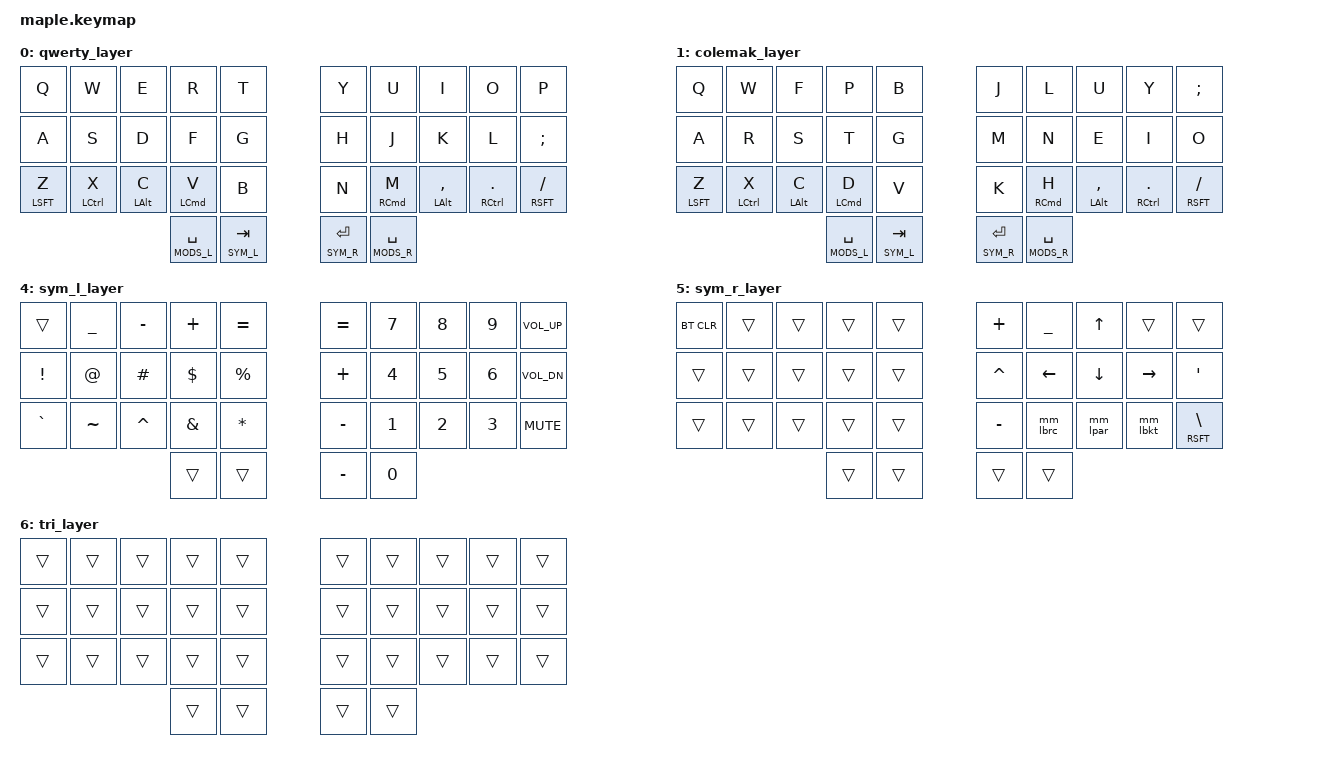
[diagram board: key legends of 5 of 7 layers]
/*
 * Copyright (c) 2020 The ZMK Contributors
 *
 * SPDX-License-Identifier: MIT
 */

#include <behaviors.dtsi>
#include <dt-bindings/zmk/keys.h>
#include <dt-bindings/zmk/bt.h>

#define QWERTY   0
#define COLEMAK  1 // DHm
#define MODS_L   2
#define MODS_R   3
#define SYM_L    4
#define SYM_R    5

&mt {
  // flavor = "tap-preferred"; // disabled here to override only for &hm keys // https://zmk.dev/docs/behaviors/hold-tap#flavors
  // tapping_term_ms = <200>;
};

/ {

  behaviors {
    // positional hold-taps (home-row)
    // - don't work with combo-arrow-keys
    lht: left_hold_tap {
      compatible = "zmk,behavior-hold-tap";
      label = "LEFT_HOLD_TAP";
      #binding-cells = <2>;
      flavor = "tap-preferred";
      tapping-term-ms = <175>;
      quick-tap-ms = <75>;
      bindings = <&kp>, <&kp>;
      hold-trigger-key-positions = <5 6 7 8 9 15 16 17 18 19 25 26 27 28 29>; // all right-side key-positions
      // <5 6 7 8 9 15 16 17 18 19 25 26 27 28 29 32 33>; // all right-side key-positions
    };
    rht: right_hold_tap {
      compatible = "zmk,behavior-hold-tap";
      label = "RIGHT_HOLD_TAP";
      #binding-cells = <2>;
      flavor = "tap-preferred";
      tapping-term-ms = <175>;
      quick-tap-ms = <75>;
      bindings = <&kp>, <&kp>;
      hold-trigger-key-positions = <0 1 2 3 4 10 11 12 13 14 20 21 22 23 24>; // all left-side key-positions
      // <0 1 2 3 4 10 11 12 13 14 20 21 22 23 24 30 31>; // all left-side key-positions
    };
    // custom behavior for only homerow-mod keys (todo: test these instead of lht&rht)
    // - should work with combo arrow-keys
    hm: homerow_mods {
      compatible = "zmk,behavior-hold-tap";
      label = "HOMEROW_MODS";
      #binding-cells = <2>;
      tapping-term-ms = <150>;
      quick-tap-ms = <0>;
      flavor = "tap-preferred";
      bindings = <&kp>, <&kp>;
    };
    // mod-morphs
    mm_lbrc: mod_morph_shft_rbrc {
      compatible = "zmk,behavior-mod-morph";
      label = "MM_SHFT_LBRC_TO_RBRC";
      #binding-cells = <0>;
      bindings = <&kp LBRC>, <&kp RBRC>;
      mods = <(MOD_LSFT|MOD_RSFT)>;
    };
    mm_lpar: mod_morph_shft_rpar {
      compatible = "zmk,behavior-mod-morph";
      label = "MM_SHFT_LPAR_TO_RPAR";
      #binding-cells = <0>;
      bindings = <&kp LPAR>, <&kp RPAR>;
      mods = <(MOD_LSFT|MOD_RSFT)>;
    };
    mm_lbkt: mod_morph_shft_rbkt {
      compatible = "zmk,behavior-mod-morph";
      label = "MM_SHFT_LBKT_TO_RBKT";
      #binding-cells = <0>;
      bindings = <&kp LBKT>, <&kp RBKT>;
      mods = <(MOD_LSFT|MOD_RSFT)>;
    };
    mm_bspc: mod_morph_shft_del {
      compatible = "zmk,behavior-mod-morph";
      label = "MM_SHFT_BSPC_TO_DEL";
      #binding-cells = <0>;
      bindings = <&kp BSPC>, <&kp DEL>;
      mods = <(MOD_LSFT|MOD_RSFT)>;
      keep-mods = <(MOD_LSFT)>;
    };
    // custom: haven't got tap-dance repeat arrow keys to work yet
    // - needed for home-row mods and arrow-combos on same base layer
    // - could maybe be combined with quick-tap to fix repeat problem
    // td_combo_right: tap_dance_combo_right {
    //   compatible = "zmk,behavior-tap-dance";
    //   label = "TD_COMBO_RIGHT";
    //   #binding-cells = <0>;
    //   tapping-term-ms = <200>;
    //   bindings =<&mt (RCTRL|RSFT) RIGHT>, <&kp RIGHT>;
    // };
    // td_combo_down: tap_dance_combo_down {
    //   compatible = "zmk,behavior-tap-dance";
    //   label = "TD_COMBO_DOWN";
    //   #binding-cells = <0>;
    //   tapping-term-ms = <200>;
    //   bindings =<&mt (LALT|RCTRL) DOWN>, <&kp DOWN>;
    // };
    // td_combo_left: tap_dance_combo_left {
    //   compatible = "zmk,behavior-tap-dance";
    //   label = "TD_COMBO_LEFT";
    //   #binding-cells = <0>;
    //   tapping-term-ms = <200>;
    //   bindings =<&mt (RCMD|LALT) LEFT>, <&kp LEFT>;
    // };
  };

  // macros {
  //   mc_hm_cmd: mc_hm_cmd {
  //     label = "MACRO_HOMEROW_CMD";
  //     compatible = "zmk,behavior-macro";
  //     #binding-cells = <0>;
  //     bindings = <&macro_press &kp LSHFT>, <&macro_tap &kp Z &kp M &kp K>, <&macro_release &kp LSHFT>;
  //   };
  // };


  //          key-positions
  //  0  1  2  3  4    5  6  7  8  9
  // 10 11 12 13 14   15 16 17 18 19
  // 20 21 22 23 24   25 26 27 28 29
  //          30 31   32 33

  combos {
    compatible = "zmk,combos";
    combo_tab {
      timeout-ms = <50>;
      key-positions = <0 1>;
      bindings = <&kp TAB>;
    };
    combo_esc {
      timeout-ms = <50>;
      key-positions = <10 11>;
      bindings = <&mt (LSFT|LCTRL) ESC>;
    };
    combo_up {
      timeout-ms = <50>;
      key-positions = <7 8>;
      bindings = <&kp UP>;
    };
    combo_right {
      timeout-ms = <50>;
      key-positions = <18 19>;
      // bindings = <&mt (RCTRL|RSFT) RIGHT>;
      bindings = <&kp RIGHT>;
    };
    combo_down {
      timeout-ms = <50>;
      key-positions = <17 18>;
      // bindings = <&mt (LALT|RCTRL) DOWN>;
      bindings = <&kp DOWN>;
    };
    combo_left {
      timeout-ms = <50>;
      key-positions = <16 17>;
      // bindings = <&mt (RCMD|LALT) LEFT>;
      bindings = <&kp LEFT>;
    };
    combo_bspc {
      timeout-ms = <50>;
      key-positions = <8 9>;
      bindings = <&mm_bspc>;
    };
    combo_qwerty {
      timeout-ms = <50>;
      key-positions = <10 19>;
      bindings = <&to QWERTY>;
    };
    combo_colemak {
      timeout-ms = <50>;
      key-positions = <20 29>;
      bindings = <&to COLEMAK>;
    };

    // Backup
    // combo_hm_l_1 { // don't work because they can't &mo and also hold the initial modifier
    //   timeout-ms = <100>;
    //   key-positions = <13 30>;
    //   bindings = <&mo MODS_L>;
    //   slow-release;
    // };
    // combo_hm_l_2 {
    //   timeout-ms = <100>;
    //   key-positions = <12 30>;
    //   bindings = <&mo MODS_L>;
    //   slow-release;
    // };
    // combo_hm_l_3 {
    //   timeout-ms = <100>;
    //   key-positions = <11 30>;
    //   bindings = <&mo MODS_L>;
    //   slow-release;
    // };
    // combo_hm_l_4 {
    //   timeout-ms = <100>;
    //   key-positions = <10 30>;
    //   bindings = <&mo MODS_L>;
    //   slow-release;
    // };
  };

  keymap {
    compatible = "zmk,keymap";

    qwerty_layer {
      bindings = <
        &kp Q       &kp W        &kp E       &kp R           &kp T              &kp Y          &kp U        &kp I           &kp O           &kp P
        &kp A       &kp S        &kp D       &kp F           &kp G              &kp H          &kp J  &kp K     &kp L    &kp SEMI
        &hm LSFT Z  &hm LCTRL X  &hm LALT C  &hm LCMD V      &kp B              &kp N          &hm RCMD M  &hm LALT CMMA  &hm RCTRL DOT  &hm RSFT FSLH
                                             &lt MODS_L SPACE   &lt SYM_L TAB      &lt SYM_R RET  &lt MODS_R SPACE
      >;
    };

    colemak_layer {
      bindings = <
        &kp Q       &kp W        &kp F       &kp P           &kp B              &kp J          &kp L       &kp U          &kp Y          &kp SEMI
        &kp A       &kp R        &kp S       &kp T           &kp G              &kp M          &kp N       &kp E          &kp I          &kp O
        &hm LSFT Z  &hm LCTRL X  &hm LALT C  &hm LCMD D      &kp V              &kp K          &hm RCMD H  &hm LALT CMMA  &hm RCTRL DOT  &hm RSFT FSLH
                                             &lt MODS_L SPACE   &lt SYM_L TAB      &lt SYM_R RET  &lt MODS_R SPACE
      >;
    };

    mods_l_layer {
      bindings = <
        &trans           &trans            &trans           &trans           &trans        &trans     &trans  &trans  &trans  &trans
        &hm LSFT &trans  &hm LCTRL &trans  &hm LALT &trans  &hm LCMD &trans  &trans        &trans     &trans  &trans  &trans  &trans
        &trans           &trans            &trans           &trans           &trans        &trans     &trans  &trans  &trans  &trans
                                                                   &trans    &trans        &trans     &trans
      >;
    };

    mods_r_layer {
      bindings = <
        &trans  &trans  &trans  &trans    &trans         &trans  &trans           &trans           &trans            &trans
        &trans  &trans  &trans  &trans    &trans         &trans  &hm RCMD &trans  &hm LALT &trans  &hm RCTRL &trans  &hm RSFT &trans
        &trans  &trans  &trans  &trans    &trans         &trans  &trans           &trans           &trans            &trans
                                &trans    &trans         &trans  &trans
      >;
    };

    // Home-Row Symbols Backup (ie without "dedicated" arrow keys on right side hold)
    // sym_l_layer {
    //   bindings = <
    //     &trans    &trans  &trans    &trans     &trans         &trans     &kp N7  &kp N8  &kp N9  &kp C_VOL_UP
    //     &kp EXCL  &kp AT  &kp HASH  &kp DLLR   &kp PRCNT      &trans     &kp N4  &kp N5  &kp N6  &kp C_VOL_DN
    //     &trans    &trans  &trans    &kp GRAVE  &kp TILDE      &kp PLUS   &kp N1  &kp N2  &kp N3  &kp C_MUTE
    //                                 &trans     &trans         &kp MINUS  &kp N0
    //   >;
    // };

    sym_l_layer {
      bindings = <
        &trans     &kp UNDER  &kp MINUS  &kp PLUS   &kp EQUAL      &kp EQUAL  &kp N7  &kp N8  &kp N9  &kp C_VOL_UP
        &kp EXCL   &kp AT     &kp HASH   &kp DLLR   &kp PRCNT      &kp PLUS   &kp N4  &kp N5  &kp N6  &kp C_VOL_DN
        &kp GRAVE  &kp TILDE  &kp CARET  &kp AMPS   &kp STAR       &kp MINUS  &kp N1  &kp N2  &kp N3  &kp C_MUTE
                                         &trans     &trans         &kp MINUS  &kp N0
      >;
    };

    // Home-Row Symbols Backup (ie without "dedicated" arrow keys on right side hold)
    // sym_r_layer {
    //   bindings = <
    //     &bt BT_CLR    &trans  &trans    &trans    &trans         &kp PLUS   &kp UNDER  &trans    &mm_lbrc  &kp BSLH
    //     &trans        &trans  &trans    &trans    &trans         &kp CARET  &kp AMPS   &kp STAR  &mm_lpar  &kp APOS
    //     &trans        &trans  &trans    &trans    &trans         &kp MINUS  &kp EQUAL  &kp PIPE  &mm_lbkt  &kp BSLH
    //                                     &trans    &trans         &trans     &trans
    //   >;
    // };

    sym_r_layer {
      bindings = <
        &bt BT_CLR    &trans  &trans    &trans    &trans         &kp PLUS   &kp UNDER  &kp UP     &trans     &trans
        &trans        &trans  &trans    &trans    &trans         &kp CARET  &kp LEFT   &kp DOWN   &kp RIGHT  &kp APOS
        &trans        &trans  &trans    &trans    &trans         &kp MINUS  &mm_lbrc   &mm_lpar   &mm_lbkt   &hm RSFT BSLH
                                        &trans    &trans         &trans     &trans
      >;
    };

    tri_layer {
      bindings = <
        &trans  &trans  &trans    &trans    &trans         &trans     &trans  &trans  &trans  &trans
        &trans  &trans  &trans    &trans    &trans         &trans     &trans  &trans  &trans  &trans
        &trans  &trans  &trans    &trans    &trans         &trans     &trans  &trans  &trans  &trans
                                  &trans    &trans         &trans     &trans
      >;
    };

    // Backup lht/rht base layers
    // qwerty_layer {
    //   bindings = <
    //     &kp Q        &kp W         &kp E        &kp R            &kp T              &kp Y          &kp U        &kp I           &kp O           &kp P
    //     &lht LSFT A  &lht LCTRL S  &lht LALT D  &lht LCMD F      &kp G              &kp H          &rht RCMD J  &rht LALT K     &rht RCTRL L    &rht RSFT SEMI
    //     &lht LSFT Z  &lht LCTRL X  &lht LALT C  &lht LCMD V      &kp B              &kp N          &rht RCMD M  &rht LALT CMMA  &rht RCTRL DOT  &rht RSFT FSLH
    //                                              &mt LCMD SPACE  &lt SYM_L TAB      &lt SYM_R RET  &kp SPACE
    //   >;
    // };

    // colemak_layer {
    //   bindings = <
    //     &kp Q        &kp W         &kp F        &kp P            &kp B              &kp J          &kp L        &kp U           &kp Y           &kp APOS
    //     &lht LSFT A  &lht LCTRL R  &lht LALT S  &lht LCMD T      &kp G              &kp M          &rht RCMD N  &rht LALT E     &rht RCTRL I    &rht RSFT O
    //     &lht LSFT Z  &lht LCTRL X  &lht LALT C  &lht LCMD D      &kp V              &kp K          &rht RCMD H  &rht LALT CMMA  &rht RCTRL DOT  &rht RSFT FSLH
    //                                              &mt LCMD SPACE  &lt SYM_L TAB      &lt SYM_R RET  &kp SPACE
    //   >;
    // };

    // Backup pure base layers
    // qwerty_layer {
    //   bindings = <
    //     &kp Q  &kp W  &kp E  &kp R      &kp T        &kp Y          &kp U        &kp I           &kp O           &kp P
    //     &kp A  &kp S  &kp D  &kp F      &kp G              &kp H          &kp J  &kp K     &kp L    &kp SEMI
    //     &kp Z  &kp X  &kp C  &kp V      &kp B              &kp N          &kp M  &kp CMMA  &kp DOT  &kp FSLH
    //                                              &lt MODS_L SPACE  &lt SYM_L TAB      &lt SYM_R RET  &lt MODS_R SPACE
    //   >;
    // };

    // colemak_layer {
    //   bindings = <
    //     &kp Q        &kp W         &kp F        &kp P            &kp B              &kp J          &kp L        &kp U           &kp Y           &kp APOS
    //     &kp A  &kp R  &kp S  &kp T      &kp G              &kp M          &kp N  &kp E     &kp I    &kp O
    //     &kp Z  &kp X  &kp C  &kp D      &kp V              &kp K          &kp H  &kp CMMA  &kp DOT  &kp FSLH
    //                                              &lt MODS_L SPACE  &lt SYM_L TAB      &lt SYM_R RET  &lt MODS_R SPACE
    //   >;
    // };
  };
};
